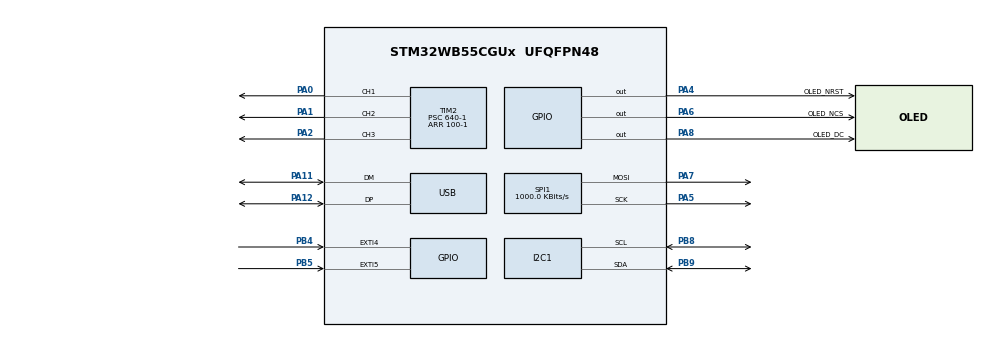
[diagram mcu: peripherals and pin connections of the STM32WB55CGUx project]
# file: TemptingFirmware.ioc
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I2C1.Timing=0x10B17DB5
Mcu.Family=STM32WB
Mcu.Name=STM32WB55CGUx
Mcu.Package=UFQFPN48
NVIC.EXTI4_IRQn=true\:0\:0\:false\:false\:true\:true\:true\:true
NVIC.EXTI9_5_IRQn=true\:0\:0\:false\:false\:true\:true\:true\:true
NVIC.HSEM_IRQn=true\:0\:0\:false\:false\:true\:false\:true\:true
NVIC.IPCC_C1_RX_IRQn=true\:0\:0\:false\:false\:true\:true\:true\:true
NVIC.IPCC_C1_TX_IRQn=true\:0\:0\:false\:false\:true\:true\:true\:true
NVIC.PriorityGroup=NVIC_PRIORITYGROUP_4
NVIC.RTC_WKUP_IRQn=true\:0\:0\:false\:false\:true\:true\:true\:true
NVIC.USB_LP_IRQn=true\:0\:0\:false\:false\:true\:false\:true\:true
OSC_IN.Mode=HSE-External-Oscillator
OSC_IN.Signal=RCC_OSC_IN
OSC_OUT.Mode=HSE-External-Oscillator
OSC_OUT.Signal=RCC_OSC_OUT
PA0.Signal=S_TIM2_CH1
PA1.Signal=S_TIM2_CH2
PA11.Mode=Device
PA11.Signal=USB_DM
PA12.Mode=Device
PA12.Signal=USB_DP
PA13.Mode=Trace_Asynchronous_SW
PA13.Signal=SYS_JTMS-SWDIO
PA14.Mode=Trace_Asynchronous_SW
PA14.Signal=SYS_JTCK-SWCLK
PA2.Signal=S_TIM2_CH3
PA4.GPIO_Label=OLED_NRST
PA4.Signal=GPIO_Output
PA5.Mode=TX_Only_Simplex_Unidirect_Master
PA5.Signal=SPI1_SCK
PA6.GPIO_Label=OLED_NCS
PA6.Signal=GPIO_Output
PA7.Mode=TX_Only_Simplex_Unidirect_Master
PA7.Signal=SPI1_MOSI
PA8.GPIO_Label=OLED_DC
PA8.Signal=GPIO_Output
PB3.Mode=Trace_Asynchronous_SW
PB3.Signal=SYS_JTDO-SWO
PB4.GPIO_ModeDefaultEXTI=GPIO_MODE_IT_FALLING
PB4.GPIO_PuPd=GPIO_PULLUP
PB4.Signal=GPXTI4
PB5.GPIO_ModeDefaultEXTI=GPIO_MODE_IT_FALLING
PB5.GPIO_PuPd=GPIO_PULLUP
PB5.Signal=GPXTI5
PB8.Mode=I2C
PB8.Signal=I2C1_SCL
PB9.Mode=I2C
PB9.Signal=I2C1_SDA
PC14-OSC32_IN.Mode=LSE-External-Oscillator
PC14-OSC32_IN.Signal=RCC_OSC32_IN
PC15-OSC32_OUT.Mode=LSE-External-Oscillator
PC15-OSC32_OUT.Signal=RCC_OSC32_OUT
ProjectManager.HeapSize=0x200
ProjectManager.StackSize=0x400
ProjectManager.TargetToolchain=STM32CubeIDE
RCC.ADCFreq_Value=48000000
RCC.AHB2CLKDivider=RCC_SYSCLK_DIV2
RCC.AHBFreq_Value=64000000
RCC.APB1Freq_Value=64000000
RCC.APB1TimFreq_Value=64000000
RCC.APB2Freq_Value=64000000
RCC.APB2TimFreq_Value=64000000
RCC.APB3Freq_Value=16000000
RCC.CortexFreq_Value=64000000
RCC.HCLKFreq_Value=64000000
RCC.HSE_VALUE=32000000
RCC.HSI48_VALUE=48000000
RCC.HSI_VALUE=16000000
RCC.PLLN=32
RCC.PLLSAI1N=24
RCC.RTCClockSelection=RCC_RTCCLKSOURCE_LSE
RCC.SYSCLKFreq_VALUE=64000000
RCC.SYSCLKSource=RCC_SYSCLKSOURCE_PLLCLK
RCC.USBFreq_Value=48000000
RCC.VCOOutputFreq_Value=128000000
RF1.Mode=RF1_Activate
RF1.Signal=RF_RF1
SH.S_TIM2_CH1.0=TIM2_CH1,PWM Generation1 CH1
SH.S_TIM2_CH2.0=TIM2_CH2,PWM Generation2 CH2
SH.S_TIM2_CH3.0=TIM2_CH3,PWM Generation3 CH3
SPI1.BaudRatePrescaler=SPI_BAUDRATEPRESCALER_64
SPI1.CalculateBaudRate=1000.0 KBits/s
SPI1.DataSize=SPI_DATASIZE_8BIT
SPI1.Direction=SPI_DIRECTION_2LINES
SPI1.Mode=SPI_MODE_MASTER
SPI1.VirtualType=VM_MASTER
STM32_WPAN.CFG_LSCLK_LSE=0
STM32_WPAN.ENDPOINT1_DEVICE_ID=ZCL_DEVICE_SIMPLE_SENSOR
STM32_WPAN.ZCL_IDENTIFY_ENDPOINT1=SERVER
STM32_WPAN.ZCL_PRESSURE_MEASUREMENT_ENDPOINT1=SERVER
STM32_WPAN.ZCL_TEMPERATURE_MEASUREMENT_ENDPOINT1=SERVER
STM32_WPAN.ZCL_THERMOSTAT_ENDPOINT1=NONE
STM32_WPAN.ZGB_APPLICATION=RFD
STM32_WPAN.ZGB_CHANNEL=25
STM32_WPAN.ZGB_NW_MODE=CENTRALIZED
TIM2.Channel-PWM\ Generation1\ CH1=TIM_CHANNEL_1
TIM2.Channel-PWM\ Generation2\ CH2=TIM_CHANNEL_2
TIM2.Channel-PWM\ Generation3\ CH3=TIM_CHANNEL_3
TIM2.Period=100-1
TIM2.Prescaler=640-1
USB_DEVICE.CLASS_NAME_FS=CDC
USB_DEVICE.VirtualMode=Cdc
USB_DEVICE.VirtualModeFS=Cdc_FS
VP_HSEM_VS_HSEM.Mode=HSEM_Activate
VP_IPCC_VS_IPCC.Mode=IPCC_Activate
VP_MEMORYMAP_VS_MEMORYMAP.Mode=CurAppReg
VP_RTC_VS_RTC_Activate.Mode=RTC_Enabled
VP_RTC_VS_RTC_WakeUp_intern.Mode=WakeUp
VP_SEQUENCER_VS_SEQUENCER.Mode=SEQUENCER_Enabled
VP_STM32_WPAN_VS_ZIGBEE.Mode=MOD_ZGB_ENDPOINT
VP_TINY_LPM_VS_TINY_LPM.Mode=TINY_LPM_Enabled
VP_USB_DEVICE_VS_USB_DEVICE_CDC_FS.Mode=CDC_FS
board=custom

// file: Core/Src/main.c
/* USER CODE BEGIN Header */
/**
  ******************************************************************************
  * @file           : main.c
  * @brief          : Main program body
  ******************************************************************************
  * @attention
  *
  * Copyright (c) 2025 STMicroelectronics.
  * All rights reserved.
  *
  * This software is licensed under terms that can be found in the LICENSE file
  * in the root directory of this software component.
  * If no LICENSE file comes with this software, it is provided AS-IS.
  *
  ******************************************************************************
  */
/* USER CODE END Header */
#include "main.h"
#include "i2c.h"
#include "ipcc.h"
#include "memorymap.h"
#include "rf.h"
#include "rtc.h"
#include "spi.h"
#include "tim.h"
#include "usb_device.h"
#include "gpio.h"

/* USER CODE BEGIN Includes */
#include "DPS368-Barometer.h"
#include "SCD41-CO2Sensor.h"
#include "SSD1309-OLED.h"
#include "RGB_LED.h"
#include "usbd_cdc_if.h"
/* USER CODE END Includes */

void SystemClock_Config(void);
void PeriphCommonClock_Config(void);

/* USER CODE BEGIN 0 */
int _write(int file, char *ptr, int len)
{
    while (CDC_Transmit_FS((uint8_t *)ptr, len) == USBD_BUSY) {
        // Optional: delay or yield to avoid USB deadlock
    }
    return len;
}
/* USER CODE END 0 */

int main(void)
{

  /* MCU Configuration--------------------------------------------------------*/

  /* Reset of all peripherals, Initializes the Flash interface and the Systick. */
  HAL_Init();
  /* Config code for STM32_WPAN (HSE Tuning must be done before system clock configuration) */
  MX_APPE_Config();

  /* Configure the system clock */
  SystemClock_Config();

  /* Configure the peripherals common clocks */
  PeriphCommonClock_Config();

  /* IPCC initialisation */
  MX_IPCC_Init();

  /* Initialize all configured peripherals */
  MX_GPIO_Init();
  MX_I2C1_Init();
  MX_SPI1_Init();
  MX_TIM2_Init();
  MX_RTC_Init();
  MX_USB_Device_Init();
  MX_RF_Init();
  /* USER CODE BEGIN 2 */
  RGB_LED_Init();
  RGB_LED_Set_Intensity(RGB_LED_RED_MAX_INTENSITY,0,0);

  DPS368_Init();
  SSD1309_Init();
  SCD41_StopPeriodicMeasurement();
  SCD41_StartPeriodicMeasurement();
  /* USER CODE END 2 */

  /* Init code for STM32_WPAN */
  MX_APPE_Init();

  /* Infinite loop */
  while (1)
  {
    MX_APPE_Process();

  }
}

void SystemClock_Config(void)
{
  RCC_OscInitTypeDef RCC_OscInitStruct = {0};
  RCC_ClkInitTypeDef RCC_ClkInitStruct = {0};

  /** Configure LSE Drive Capability
  */
  HAL_PWR_EnableBkUpAccess();
  __HAL_RCC_LSEDRIVE_CONFIG(RCC_LSEDRIVE_MEDIUMHIGH);

  /** Configure the main internal regulator output voltage
  */
  __HAL_PWR_VOLTAGESCALING_CONFIG(PWR_REGULATOR_VOLTAGE_SCALE1);

  /** Initializes the RCC Oscillators according to the specified parameters
  * in the RCC_OscInitTypeDef structure.
  */
  RCC_OscInitStruct.OscillatorType = RCC_OSCILLATORTYPE_HSI|RCC_OSCILLATORTYPE_HSE
                              |RCC_OSCILLATORTYPE_LSE|RCC_OSCILLATORTYPE_MSI;
  RCC_OscInitStruct.HSEState = RCC_HSE_ON;
  RCC_OscInitStruct.LSEState = RCC_LSE_ON;
  RCC_OscInitStruct.HSIState = RCC_HSI_ON;
  RCC_OscInitStruct.MSIState = RCC_MSI_ON;
  RCC_OscInitStruct.HSICalibrationValue = RCC_HSICALIBRATION_DEFAULT;
  RCC_OscInitStruct.MSICalibrationValue = RCC_MSICALIBRATION_DEFAULT;
  RCC_OscInitStruct.MSIClockRange = RCC_MSIRANGE_6;
  RCC_OscInitStruct.PLL.PLLState = RCC_PLL_ON;
  RCC_OscInitStruct.PLL.PLLSource = RCC_PLLSOURCE_MSI;
  RCC_OscInitStruct.PLL.PLLM = RCC_PLLM_DIV1;
  RCC_OscInitStruct.PLL.PLLN = 32;
  RCC_OscInitStruct.PLL.PLLP = RCC_PLLP_DIV2;
  RCC_OscInitStruct.PLL.PLLR = RCC_PLLR_DIV2;
  RCC_OscInitStruct.PLL.PLLQ = RCC_PLLQ_DIV2;
  if (HAL_RCC_OscConfig(&RCC_OscInitStruct) != HAL_OK)
  {
    Error_Handler();
  }

  /** Configure the SYSCLKSource, HCLK, PCLK1 and PCLK2 clocks dividers
  */
  RCC_ClkInitStruct.ClockType = RCC_CLOCKTYPE_HCLK4|RCC_CLOCKTYPE_HCLK2
                              |RCC_CLOCKTYPE_HCLK|RCC_CLOCKTYPE_SYSCLK
                              |RCC_CLOCKTYPE_PCLK1|RCC_CLOCKTYPE_PCLK2;
  RCC_ClkInitStruct.SYSCLKSource = RCC_SYSCLKSOURCE_PLLCLK;
  RCC_ClkInitStruct.AHBCLKDivider = RCC_SYSCLK_DIV1;
  RCC_ClkInitStruct.APB1CLKDivider = RCC_HCLK_DIV1;
  RCC_ClkInitStruct.APB2CLKDivider = RCC_HCLK_DIV1;
  RCC_ClkInitStruct.AHBCLK2Divider = RCC_SYSCLK_DIV2;
  RCC_ClkInitStruct.AHBCLK4Divider = RCC_SYSCLK_DIV1;

  if (HAL_RCC_ClockConfig(&RCC_ClkInitStruct, FLASH_LATENCY_3) != HAL_OK)
  {
    Error_Handler();
  }

  /** Enable MSI Auto calibration
  */
  HAL_RCCEx_EnableMSIPLLMode();
}

void PeriphCommonClock_Config(void)
{
  RCC_PeriphCLKInitTypeDef PeriphClkInitStruct = {0};

  LL_HSEM_1StepLock( HSEM, 5 );

  /** Initializes the peripherals clock
  */
  PeriphClkInitStruct.PeriphClockSelection = RCC_PERIPHCLK_SMPS|RCC_PERIPHCLK_RFWAKEUP;
  PeriphClkInitStruct.RFWakeUpClockSelection = RCC_RFWKPCLKSOURCE_HSE_DIV1024;
  PeriphClkInitStruct.SmpsClockSelection = RCC_SMPSCLKSOURCE_HSI;
  PeriphClkInitStruct.SmpsDivSelection = RCC_SMPSCLKDIV_RANGE1;

  if (HAL_RCCEx_PeriphCLKConfig(&PeriphClkInitStruct) != HAL_OK)
  {
    Error_Handler();
  }
}

void Error_Handler(void)
{
  __disable_irq();
  while (1)
  {
  }
}
